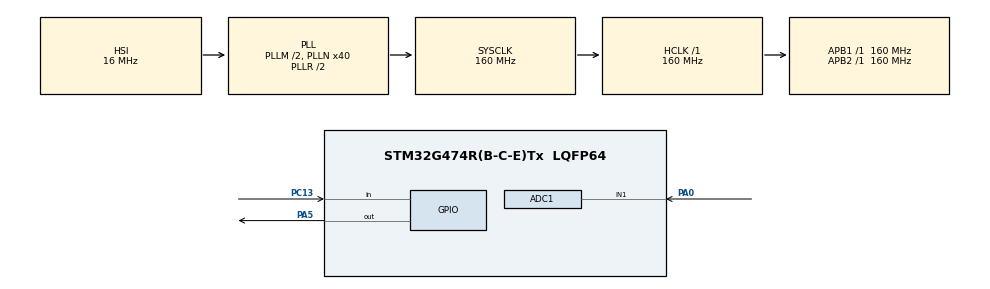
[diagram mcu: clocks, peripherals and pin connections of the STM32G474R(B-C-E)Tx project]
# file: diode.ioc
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ADC1.Channel-0\#ChannelRegularConversion=ADC_CHANNEL_1
ADC1.ClockPrescaler=ADC_CLOCK_ASYNC_DIV16
ADC1.NbrOfConversionFlag=1
ADC1.OffsetNumber-0\#ChannelRegularConversion=ADC_OFFSET_NONE
ADC1.Rank-0\#ChannelRegularConversion=1
ADC1.SamplingTime-0\#ChannelRegularConversion=ADC_SAMPLETIME_2CYCLES_5
ADC1.master=1
Mcu.Family=STM32G4
Mcu.Name=STM32G474R(B-C-E)Tx
Mcu.Package=LQFP64
NVIC.PriorityGroup=NVIC_PRIORITYGROUP_4
NVIC.TIM1_TRG_COM_TIM17_IRQn=true\:0\:0\:false\:false\:true\:true\:true
PA0.Mode=IN1-Single-Ended
PA0.Signal=ADC1_IN1
PA5.Signal=GPIO_Output
PC13.GPIO_PuPd=GPIO_PULLDOWN
PC13.Signal=GPIO_Input
ProjectManager.HeapSize=0x200
ProjectManager.StackSize=0x400
ProjectManager.TargetToolchain=MDK-ARM V5.27
RCC.ADC12Freq_Value=160000000
RCC.ADC345Freq_Value=160000000
RCC.AHBFreq_Value=160000000
RCC.APB1Freq_Value=160000000
RCC.APB1TimFreq_Value=160000000
RCC.APB2Freq_Value=160000000
RCC.APB2TimFreq_Value=160000000
RCC.CortexFreq_Value=160000000
RCC.EXTERNAL_CLOCK_VALUE=12288000
RCC.HCLKFreq_Value=160000000
RCC.HSE_VALUE=8000000
RCC.HSI48_VALUE=48000000
RCC.HSI_VALUE=16000000
RCC.LSE_VALUE=32768
RCC.PLLM=RCC_PLLM_DIV2
RCC.PLLN=40
RCC.SYSCLKFreq_VALUE=160000000
RCC.SYSCLKSource=RCC_SYSCLKSOURCE_PLLCLK
RCC.USBFreq_Value=160000000
RCC.VCOOutputFreq_Value=320000000
TIM17.PeriodNoDither=9999
TIM17.Prescaler=15999
VP_SYS_VS_DBSignals.Mode=DisableDeadBatterySignals
VP_TIM17_VS_ClockSourceINT.Mode=Enable_Timer
board=custom

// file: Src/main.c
/* USER CODE BEGIN Header */
/**
  ******************************************************************************
  * @file           : main.c
  * @brief          : Main program body
  ******************************************************************************
  * @attention
  *
  * <h2><center>&copy; Copyright (c) 2021 STMicroelectronics.
  * All rights reserved.</center></h2>
  *
  * This software component is licensed by ST under BSD 3-Clause license,
  * the "License"; You may not use this file except in compliance with the
  * License. You may obtain a copy of the License at:
  *                        opensource.org/licenses/BSD-3-Clause
  *
  ******************************************************************************
  */
/* USER CODE END Header */

#include "main.h"

/* USER CODE BEGIN Includes */
#include "my_main.h"
/* USER CODE END Includes */

ADC_HandleTypeDef hadc1;

TIM_HandleTypeDef htim17;

void SystemClock_Config(void);
static void MX_GPIO_Init(void);
static void MX_TIM17_Init(void);
static void MX_ADC1_Init(void);

int main(void)
{

  /* MCU Configuration--------------------------------------------------------*/

  /* Reset of all peripherals, Initializes the Flash interface and the Systick. */
  HAL_Init();

  /* Configure the system clock */
  SystemClock_Config();

  /* Initialize all configured peripherals */
  MX_GPIO_Init();
  MX_TIM17_Init();
  MX_ADC1_Init();

  /* Infinite loop */
  /* USER CODE BEGIN WHILE */
	MyMain();
  /* USER CODE END 3 */
}

void SystemClock_Config(void)
{
  RCC_OscInitTypeDef RCC_OscInitStruct = {0};
  RCC_ClkInitTypeDef RCC_ClkInitStruct = {0};
  RCC_PeriphCLKInitTypeDef PeriphClkInit = {0};

  /** Configure the main internal regulator output voltage
  */
  HAL_PWREx_ControlVoltageScaling(PWR_REGULATOR_VOLTAGE_SCALE1_BOOST);
  /** Initializes the CPU, AHB and APB busses clocks
  */
  RCC_OscInitStruct.OscillatorType = RCC_OSCILLATORTYPE_HSI;
  RCC_OscInitStruct.HSIState = RCC_HSI_ON;
  RCC_OscInitStruct.HSICalibrationValue = RCC_HSICALIBRATION_DEFAULT;
  RCC_OscInitStruct.PLL.PLLState = RCC_PLL_ON;
  RCC_OscInitStruct.PLL.PLLSource = RCC_PLLSOURCE_HSI;
  RCC_OscInitStruct.PLL.PLLM = RCC_PLLM_DIV2;
  RCC_OscInitStruct.PLL.PLLN = 40;
  RCC_OscInitStruct.PLL.PLLP = RCC_PLLP_DIV2;
  RCC_OscInitStruct.PLL.PLLQ = RCC_PLLQ_DIV2;
  RCC_OscInitStruct.PLL.PLLR = RCC_PLLR_DIV2;
  if (HAL_RCC_OscConfig(&RCC_OscInitStruct) != HAL_OK)
  {
    Error_Handler();
  }
  /** Initializes the CPU, AHB and APB busses clocks
  */
  RCC_ClkInitStruct.ClockType = RCC_CLOCKTYPE_HCLK|RCC_CLOCKTYPE_SYSCLK
                              |RCC_CLOCKTYPE_PCLK1|RCC_CLOCKTYPE_PCLK2;
  RCC_ClkInitStruct.SYSCLKSource = RCC_SYSCLKSOURCE_PLLCLK;
  RCC_ClkInitStruct.AHBCLKDivider = RCC_SYSCLK_DIV1;
  RCC_ClkInitStruct.APB1CLKDivider = RCC_HCLK_DIV1;
  RCC_ClkInitStruct.APB2CLKDivider = RCC_HCLK_DIV1;

  if (HAL_RCC_ClockConfig(&RCC_ClkInitStruct, FLASH_LATENCY_7) != HAL_OK)
  {
    Error_Handler();
  }
  /** Initializes the peripherals clocks
  */
  PeriphClkInit.PeriphClockSelection = RCC_PERIPHCLK_ADC12;
  PeriphClkInit.Adc12ClockSelection = RCC_ADC12CLKSOURCE_SYSCLK;
  if (HAL_RCCEx_PeriphCLKConfig(&PeriphClkInit) != HAL_OK)
  {
    Error_Handler();
  }
}

static void MX_ADC1_Init(void)
{

  ADC_MultiModeTypeDef multimode = {0};
  ADC_ChannelConfTypeDef sConfig = {0};

  /** Common config
  */
  hadc1.Instance = ADC1;
  hadc1.Init.ClockPrescaler = ADC_CLOCK_ASYNC_DIV16;
  hadc1.Init.Resolution = ADC_RESOLUTION_12B;
  hadc1.Init.DataAlign = ADC_DATAALIGN_RIGHT;
  hadc1.Init.GainCompensation = 0;
  hadc1.Init.ScanConvMode = ADC_SCAN_DISABLE;
  hadc1.Init.EOCSelection = ADC_EOC_SINGLE_CONV;
  hadc1.Init.LowPowerAutoWait = DISABLE;
  hadc1.Init.ContinuousConvMode = DISABLE;
  hadc1.Init.NbrOfConversion = 1;
  hadc1.Init.DiscontinuousConvMode = DISABLE;
  hadc1.Init.ExternalTrigConv = ADC_SOFTWARE_START;
  hadc1.Init.ExternalTrigConvEdge = ADC_EXTERNALTRIGCONVEDGE_NONE;
  hadc1.Init.DMAContinuousRequests = DISABLE;
  hadc1.Init.Overrun = ADC_OVR_DATA_PRESERVED;
  hadc1.Init.OversamplingMode = DISABLE;
  if (HAL_ADC_Init(&hadc1) != HAL_OK)
  {
    Error_Handler();
  }
  /** Configure the ADC multi-mode
  */
  multimode.Mode = ADC_MODE_INDEPENDENT;
  if (HAL_ADCEx_MultiModeConfigChannel(&hadc1, &multimode) != HAL_OK)
  {
    Error_Handler();
  }
  /** Configure Regular Channel
  */
  sConfig.Channel = ADC_CHANNEL_1;
  sConfig.Rank = ADC_REGULAR_RANK_1;
  sConfig.SamplingTime = ADC_SAMPLETIME_2CYCLES_5;
  sConfig.SingleDiff = ADC_SINGLE_ENDED;
  sConfig.OffsetNumber = ADC_OFFSET_NONE;
  sConfig.Offset = 0;
  if (HAL_ADC_ConfigChannel(&hadc1, &sConfig) != HAL_OK)
  {
    Error_Handler();
  }

}

static void MX_TIM17_Init(void)
{

  htim17.Instance = TIM17;
  htim17.Init.Prescaler = 15999;
  htim17.Init.CounterMode = TIM_COUNTERMODE_UP;
  htim17.Init.Period = 9999;
  htim17.Init.ClockDivision = TIM_CLOCKDIVISION_DIV1;
  htim17.Init.RepetitionCounter = 0;
  htim17.Init.AutoReloadPreload = TIM_AUTORELOAD_PRELOAD_DISABLE;
  if (HAL_TIM_Base_Init(&htim17) != HAL_OK)
  {
    Error_Handler();
  }

}

static void MX_GPIO_Init(void)
{
  GPIO_InitTypeDef GPIO_InitStruct = {0};

  /* GPIO Ports Clock Enable */
  __HAL_RCC_GPIOC_CLK_ENABLE();
  __HAL_RCC_GPIOA_CLK_ENABLE();

  /*Configure GPIO pin Output Level */
  HAL_GPIO_WritePin(GPIOA, GPIO_PIN_5, GPIO_PIN_RESET);

  /*Configure GPIO pin : PC13 */
  GPIO_InitStruct.Pin = GPIO_PIN_13;
  GPIO_InitStruct.Mode = GPIO_MODE_INPUT;
  GPIO_InitStruct.Pull = GPIO_PULLDOWN;
  HAL_GPIO_Init(GPIOC, &GPIO_InitStruct);

  /*Configure GPIO pin : PA5 */
  GPIO_InitStruct.Pin = GPIO_PIN_5;
  GPIO_InitStruct.Mode = GPIO_MODE_OUTPUT_PP;
  GPIO_InitStruct.Pull = GPIO_NOPULL;
  GPIO_InitStruct.Speed = GPIO_SPEED_FREQ_LOW;
  HAL_GPIO_Init(GPIOA, &GPIO_InitStruct);

}

void Error_Handler(void)
{
}

/************************ (C) COPYRIGHT STMicroelectronics *****END OF FILE****/
